# MM32G0001 register map
File version: 0.9.0
CPU: CM0 r0p0, little endian, no MPU, no FPU, 2 interrupt priority bits
Registers are 32-bit, read-write, reset 0x0 unless marked. A register's access mark holds for its fields unless they carry their own. Offsets are from the block's base; lines under a group give offsets from that group; [hi:lo] are bit positions; {n}, {i} and the like mark numbered series; 'fields as' and 'values as' point back to an identical list; <NAME> marks a mode.

## Memory map
0x1FFFF7E8 DEVICE size 0x400
0x40000400 TIM3 size 0x400 — General purpose timer
0x40003000 IWDG size 0x400 — Independent watchdog
0x40004400 USART2 size 0x400
0x40005400 I2C1 size 0x400 — Inter integrated circuit
0x40007000 PWR size 0x400 — Power control
0x40010000 SYSCFG size 0x400 — System Configurationcontroller
0x40010400 EXTI size 0x400 — External interrupt/event controller
0x40012400 ADC1 size 0x400 — Analog to digital converter 1
0x40012C00 TIM1 size 0x400 — Advanced timer
0x40013000 SPI1 size 0x400 — Serial peripheral interface
0x40013400 DBG size 0x40 — Debug support
0x40013800 USART1 size 0x400
0x40014000 TIM14 size 0x400 — Basic purpose timer
0x40021000 RCC size 0x400 — Reset and clock control
0x40022000 FLASH size 0x400
0x40023000 CRC size 0x400 — CRC calculation unit
0x48000000 GPIOA size 0x400 — General purpose I/O
0x48000400 GPIOB size 0x400 — General purpose I/O

## Interrupts
1 PVD (PWR) — PVD through EXTI line detection interrupt
3 FLASH — Flash global interrupt
4 RCC — RCC global interrupt
5 EXTI0_1 (EXTI) — EXTI Line0_1 interrupt
6 EXTI2_3 (EXTI) — EXTI Line2_3 interrupt
7 EXTI4_15 (EXTI) — EXTI Line4_15 interrupt
12 ADC1 — ADC1 global interrupt
13 TIM1_BRK_UP_TRG_COM (TIM1) — TIM1 break,Update,Trigger and Commutation interrupt
14 TIM1_CC (TIM1) — TIM1 Capture Compare interrupt
16 TIM3 — TIM3 global interrupt
19 TIM14 — TIM14 global interrupt
23 I2C1 — I2C1 interrupt
25 SPI1 — SPI1 global interrupt
27 USART1 — USART1 global interrupt
28 USART2 — USART2 global interrupt

## ADC1 — Analog to digital converter 1
Base 0x40012400
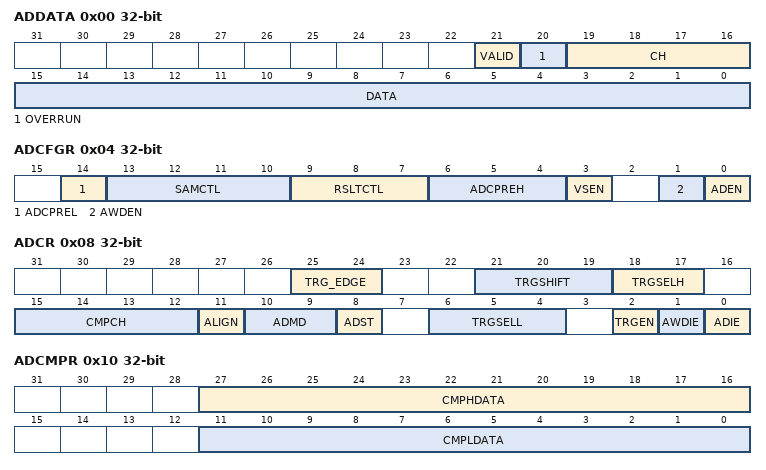
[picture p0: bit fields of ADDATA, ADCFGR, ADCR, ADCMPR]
0x00 ADDATA ro — Data register
  [21] VALID — Valid flag
  [20] OVERRUN — Overrun flag
  [19:16] CH — Channel selection
  [15:0] DATA — Transfer data
0x04 ADCFGR — Configure register
  [14] ADCPREL — ADC low prescaler coefficient
  [13:10] SAMCTL — Channel x Sample time selection
  [9:7] RSLTCTL — Resolution
  [6:4] ADCPREH — ADC high prescaler coefficient
  [3] VSEN — Reference voltage enable
  [1] AWDEN — ADC window comparison enable
  [0] ADEN — ADC enable
0x08 ADCR — Control register
  [25:24] TRG_EDGE — Trigger edge selection
  [21:19] TRGSHIFT — External trigger shift sample
  [18:17] TRGSELH — External trigger selection high
  [15:12] CMPCH — Window comparison channel selection
  [11] ALIGN — Data alignment
  [10:9] ADMD — ADC mode
  [8] ADST — ADC start
  [6:4] TRGSELL — External trigger selection low
  [2] TRGEN — External trigger enable
  [1] AWDIE — ADC window comparator interrupt enable
  [0] ADIE — ADC interrupt enable
0x10 ADCMPR — Compare register
  [27:16] CMPHDATA — Compare data high limit
  [11:0] CMPLDATA — Compare data low limit
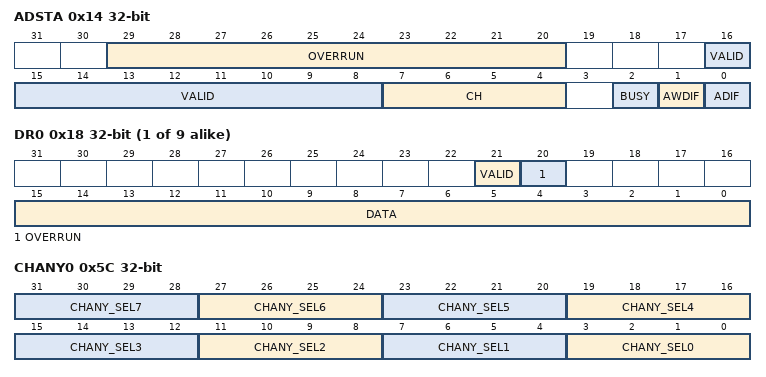
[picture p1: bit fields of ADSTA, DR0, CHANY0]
0x14 ADSTA ro — Status register
  [29:20] OVERRUN — Overrun flag
  [16:8] VALID — Valid flag
  [7:4] CH — Current conversion channel
  [2] BUSY
  [1] AWDIF — ADC window comparator interrupt flag
  [0] ADIF — ADC interrupt flag
{0x18+4i} DR{i} ro (i=0..8) — Channel {i} data register
  [21] VALID — Valid flag
  [20] OVERRUN — Overrun flag
  [15:0] DATA — Transfer data
0x5C CHANY0 — Arbitrary channel channel selection register 0
  [4n+3:4n] CHANY_SEL{n} (n=0..7) — Can be configured as any channel from ch0 to 9, 14 to 15.
0x60 CHANY1 — Arbitrary channel channel selection register 1
  [3:0] CHANY_SEL8 — *D0
0x64 ANY_CFG — Arbitrary channel configuration register
  [3:0] CHANY_NUM — channel number configuration
0x68 ANY_CR — Arbitrary channel control register
  [0] CHANY_MDEN — Any channel configuration mode enable bit

## CRC — CRC calculation unit
Base 0x40023000
0x00 DR reset 0xFFFFFFFF — Data register
  [31:0] DR — Data register bits
0x04 IDR — Independent data register
  [7:0] IDR — General-purpose 8-bit data register bits
0x08 CTRL wo — Control register
  [0] RESET — CRC reset
